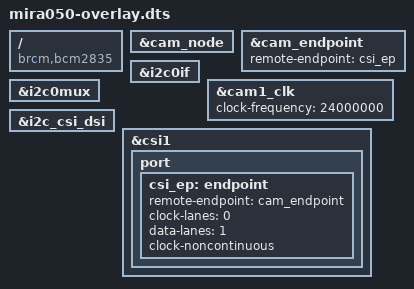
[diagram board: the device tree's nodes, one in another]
// SPDX-License-Identifier: GPL-2.0-only
// Definitions for MIRA050 camera module on VC I2C bus
/dts-v1/;
/plugin/;


/{
	compatible = "brcm,bcm2835";

	fragment@0 {
		target = <&i2c0if>;
		__overlay__ {
			status = "okay";
		};
	};

	clk_frag: fragment@1 {
		target = <&cam1_clk>;
		__overlay__ {
			status = "okay";
			clock-frequency = <24000000>;
		};
	};

	fragment@2 {
		target = <&i2c0mux>;
		__overlay__ {
			status = "okay";
		};
	};

	i2c_frag: fragment@100 {
		target = <&i2c_csi_dsi>;
		__overlay__ {
			#address-cells = <1>;
			#size-cells = <0>;
			status = "okay";

			/include/ "mira050.dtsi"

		};
	};

	csi_frag: fragment@101 {
		target = <&csi1>;
		csi: __overlay__ {
			status = "okay";

			port {
				csi_ep: endpoint {
					remote-endpoint = <&cam_endpoint>;
					clock-lanes = <0>;
					data-lanes = <1>;
					clock-noncontinuous; // mira050 use noncont clk
				};
			};
		};
	};

	__overrides__ {
		rotation = <&cam_node>,"rotation:0";
		orientation = <&cam_node>,"orientation:0";
		media-controller = <0>;
		// --- Added Mono Override ---
        mono = <&cam_node>,"mira,mono?";
		cam0 = <&i2c_frag>, "target:0=",<&i2c_csi_dsi0>,
		       <&csi_frag>, "target:0=",<&csi0>,
		       <&clk_frag>, "target:0=",<&cam0_clk>,
		       <&cam_node>, "clocks:0=",<&cam0_clk>,
		       <&cam_node>, "vdd28-supply:0=",<&cam0_reg>;
	};
};

&cam_node {
	status = "okay";
};

&cam_endpoint {
	remote-endpoint = <&csi_ep>;
};
